# ATSAMD21G17D device description
Architecture: CORTEX-M0PLUS; Family: SAMD; Series: SAMD21
Registers are 32-bit, read-write, reset 0x0 unless marked. A register's access mark holds for its fields unless they carry their own. Offsets are from the block's base; [hi:lo] are bit positions; {n}, {i} and the like mark numbered series; 'fields as' and 'values as' point back to an identical list.

## AUX3_FUSES — Non-Volatile Fuses
Instances: AUX3_FUSES 0x0080A000 in fuses
0x0C AUX3_WORD_3 ro reset not defined — AUX3 Page Word 3
  [31:0] SERIAL_NUMBER_3 — Serial Number word 3
{0x0+4i} AUX3_WORD_{i} ro reset not defined (i=16..18) — AUX3 Page Word {i}
  [31:0] SERIAL_NUMBER_{i-16} — Serial Number words 2-0 bits {32i-481}:{32i-512}

## OTP4_FUSES — Non-Volatile Fuses
Instances: OTP4_FUSES 0x00806020 in fuses
0x00 OTP4_WORD_0 ro reset not defined — OTP4 Page Word 0
  [31:27] ADC_LINEARITY_0 — ADC Linearity bits 4:0
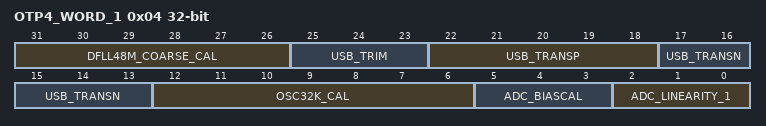
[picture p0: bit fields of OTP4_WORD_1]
0x04 OTP4_WORD_1 ro reset not defined — OTP4 Page Word 1
  [31:26] DFLL48M_COARSE_CAL — DFLL48M Coarse Calibration
  [25:23] USB_TRIM — USB pad Trim calibration
  [22:18] USB_TRANSP — USB pad Transp calibration
  [17:13] USB_TRANSN — USB pad Transn calibration
  [12:6] OSC32K_CAL — OSC32K Calibration
  [5:3] ADC_BIASCAL — ADC Bias Calibration
  [2:0] ADC_LINEARITY_1 — ADC Linearity bits 7:5
0x08 OTP4_WORD_2 ro reset not defined — OTP4 Page Word 2
  [9:0] DFLL48M_FINE_CAL — DFLL48M Fine Calibration

## TEMP_LOG_FUSES — Non-Volatile Fuses
Instances: TEMP_LOG_FUSES 0x00806030 in fuses
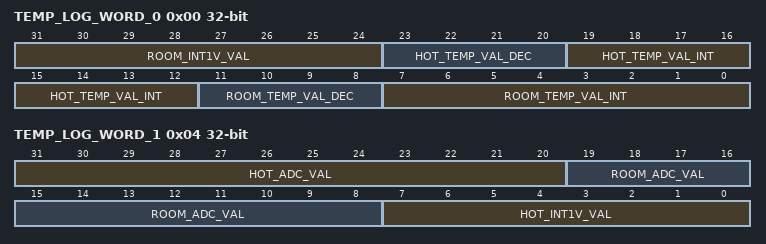
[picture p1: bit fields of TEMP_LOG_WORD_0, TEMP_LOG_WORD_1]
0x00 TEMP_LOG_WORD_0 ro reset not defined — TEMP_LOG Page Word 0
  [31:24] ROOM_INT1V_VAL — 2's complement of the internal 1V reference drift at room temperature (versus a 1.0 centered value)
  [23:20] HOT_TEMP_VAL_DEC — Decimal part of hot temperature
  [19:12] HOT_TEMP_VAL_INT — Integer part of hot temperature in oC
  [11:8] ROOM_TEMP_VAL_DEC — Decimal part of room temperature
  [7:0] ROOM_TEMP_VAL_INT — Integer part of room temperature in oC
0x04 TEMP_LOG_WORD_1 ro reset not defined — TEMP_LOG Page Word 1
  [31:20] HOT_ADC_VAL — 12-bit ADC conversion at hot temperature
  [19:8] ROOM_ADC_VAL — 12-bit ADC conversion at room temperature
  [7:0] HOT_INT1V_VAL — 2's complement of the internal 1V reference drift at hot temperature (versus a 1.0 centered value)

## USER_FUSES — Non-Volatile Fuses
Instances: USER_FUSES 0x00804000 in fuses
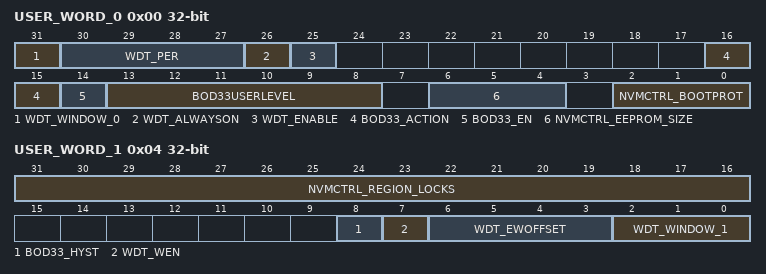
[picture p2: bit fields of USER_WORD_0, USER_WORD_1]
0x00 USER_WORD_0 reset not defined — USER Page Word 0
  [31] WDT_WINDOW_0 — WDT Window bit 0
  [30:27] WDT_PER — WDT Period
    0=8 clock cycles; 1=16 clock cycles; 2=32 clock cycles; 3=64 clock cycles; 4=128 clock cycles; 5=256 clock cycles; 6=512 clock cycles; 7=1K (1024 clock cycles); 8=2K (2048 clock cycles); 9=4K (4096 clock cycles); 10=8K (8192 clock cycles); 11=16K (16384 clock cycles)
  [26] WDT_ALWAYSON
  [25] WDT_ENABLE
  [16:15] BOD33_ACTION
    0=NONE (No action); 1=RESET (The BOD33 generates a reset); 2=INTERRUPT (The BOD33 generates an interrupt)
  [14] BOD33_EN — BOD33 Enable
  [13:8] BOD33USERLEVEL
  [6:4] NVMCTRL_EEPROM_SIZE — EEPROM Size
    7=0 Bytes; 6=256 Bytes; 5=512 Bytes; 4=1K (1024 Bytes); 3=2K (2048 Bytes); 2=4K (4096 Bytes); 1=8K (8192 Bytes); 0=16K (16384 Bytes)
  [2:0] NVMCTRL_BOOTPROT — Bootloader Size
    7=0 Bytes; 6=512 Bytes; 5=1K (1024 Bytes); 4=2K (2048 Bytes); 3=4K (4096 Bytes); 2=8K (8192 Bytes); 1=16K (16384 Bytes); 0=32K (32768 Bytes)
0x04 USER_WORD_1 reset not defined — USER Page Word 1
  [31:16] NVMCTRL_REGION_LOCKS — NVM Region Locks
  [8] BOD33_HYST — BOD33 Hysteresis
  [7] WDT_WEN — WDT Window Mode Enable
  [6:3] WDT_EWOFFSET — WDT Early Warning Offset
    values as USER_WORD_0.WDT_PER
  [2:0] WDT_WINDOW_1 — WDT Window bits 3:1

## PAC — Peripheral Access Controller
Instances: PAC0 0x40000000, PAC1 0x41000000, PAC2 0x42000000
0x00 WPCLR (atomic clear) — Write Protection Clear
  [31:1] WP
0x04 WPSET (atomic set) — Write Protection Set
  [31:1] WP

## PM — Power Manager
Instances: PM 0x40000400
0x00 CTRL 8-bit — Control
0x01 SLEEP 8-bit — Sleep Mode
  [1:0] IDLE — Idle Mode Configuration
    0=CPU (The CPU clock domain is stopped); 1=AHB (The CPU and AHB clock domains are stopped); 2=APB (The CPU, AHB and APB clock domains are stopped)
0x02 EXTCTRL 8-bit — External Reset Controller
  [0] SETDIS — External Reset Disable
0x08 CPUSEL 8-bit — CPU Clock Select
  [2:0] CPUDIV — CPU Prescaler Selection
    0=DIV1 (Divide by 1); 1=DIV2 (Divide by 2); 2=DIV4 (Divide by 4); 3=DIV8 (Divide by 8); 4=DIV16 (Divide by 16); 5=DIV32 (Divide by 32); 6=DIV64 (Divide by 64); 7=DIV128 (Divide by 128)
0x09 APBASEL 8-bit — APBA Clock Select
  [2:0] APBADIV — APBA Prescaler Selection
    values as CPUSEL.CPUDIV
0x0A APBBSEL 8-bit — APBB Clock Select
  [2:0] APBBDIV — APBB Prescaler Selection
    values as CPUSEL.CPUDIV
0x0B APBCSEL 8-bit — APBC Clock Select
  [2:0] APBCDIV — APBC Prescaler Selection
    values as CPUSEL.CPUDIV
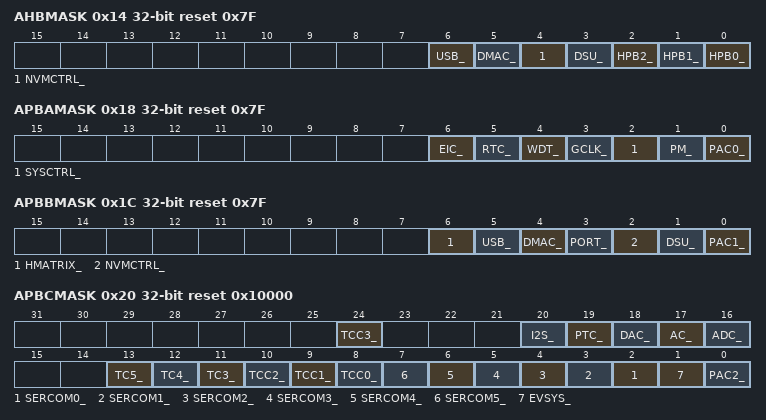
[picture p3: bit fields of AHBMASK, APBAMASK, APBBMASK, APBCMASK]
0x14 AHBMASK reset 0x7F
  [6] USB_ — USB AHB Clock Mask
  [5] DMAC_ — DMAC AHB Clock Mask
  [4] NVMCTRL_ — NVMCTRL AHB Clock Mask
  [3] DSU_ — DSU AHB Clock Mask
  [2] HPB2_ — HPB2 AHB Clock Mask
  [1] HPB1_ — HPB1 AHB Clock Mask
  [0] HPB0_ — HPB0 AHB Clock Mask
0x18 APBAMASK reset 0x7F
  [6] EIC_ — EIC APB Clock Enable
  [5] RTC_ — RTC APB Clock Enable
  [4] WDT_ — WDT APB Clock Enable
  [3] GCLK_ — GCLK APB Clock Enable
  [2] SYSCTRL_ — SYSCTRL APB Clock Enable
  [1] PM_ — PM APB Clock Enable
  [0] PAC0_ — PAC0 APB Clock Enable
0x1C APBBMASK reset 0x7F
  [6] HMATRIX_ — HMATRIX APB Clock Enable
  [5] USB_ — USB APB Clock Enable
  [4] DMAC_ — DMAC APB Clock Enable
  [3] PORT_ — PORT APB Clock Enable
  [2] NVMCTRL_ — NVMCTRL APB Clock Enable
  [1] DSU_ — DSU APB Clock Enable
  [0] PAC1_ — PAC1 APB Clock Enable
0x20 APBCMASK reset 0x10000
  [24] TCC3_ — TCC3 APB Clock Enable
  [20] I2S_ — I2S APB Clock Enable
  [19] PTC_ — PTC APB Clock Enable
  [18] DAC_ — DAC APB Clock Enable
  [17] AC_ — AC APB Clock Enable
  [16] ADC_ — ADC APB Clock Enable
  [13] TC5_ — TC5 APB Clock Enable
  [12] TC4_ — TC4 APB Clock Enable
  [11] TC3_ — TC3 APB Clock Enable
  [10] TCC2_ — TCC2 APB Clock Enable
  [9] TCC1_ — TCC1 APB Clock Enable
  [8] TCC0_ — TCC0 APB Clock Enable
  [n+2] SERCOM{n}_ (n=0..5) — SERCOM{n} APB Clock Enable
  [1] EVSYS_ — EVSYS APB Clock Enable
  [0] PAC2_ — PAC2 APB Clock Enable
0x34 INTENCLR 8-bit (atomic clear) — Interrupt Enable Clear
  [0] CKRDY — Clock Ready Interrupt Enable
0x35 INTENSET 8-bit (atomic set) — Interrupt Enable Set
  [0] CKRDY — Clock Ready Interrupt Enable
0x36 INTFLAG 8-bit (atomic clear) — Interrupt Flag Status and Clear
  [0] CKRDY — Clock Ready
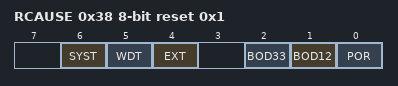
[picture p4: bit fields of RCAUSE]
0x38 RCAUSE 8-bit ro reset 0x1 — Reset Cause
  [6] SYST — System Reset Request
  [5] WDT — Watchdog Reset
  [4] EXT — External Reset
  [2] BOD33 — Brown Out 33 Detector Reset
  [1] BOD12 — Brown Out 12 Detector Reset
  [0] POR — Power On Reset

## Notices in the file
Copyright (c) 2018 Microchip Technology Inc.
SPDX-License-Identifier: Apache-2.0
Licensed under the Apache License, Version 2.0 (the "License");
you may not use this file except in compliance with the License.
You may obtain a copy of the License at
http://www.apache.org/licenses/LICENSE-2.0
Unless required by applicable law or agreed to in writing, software
distributed under the License is distributed on an "AS IS" BASIS,
WITHOUT WARRANTIES OR CONDITIONS OF ANY KIND, either express or implied.
See the License for the specific language governing permissions and
limitations under the License.
